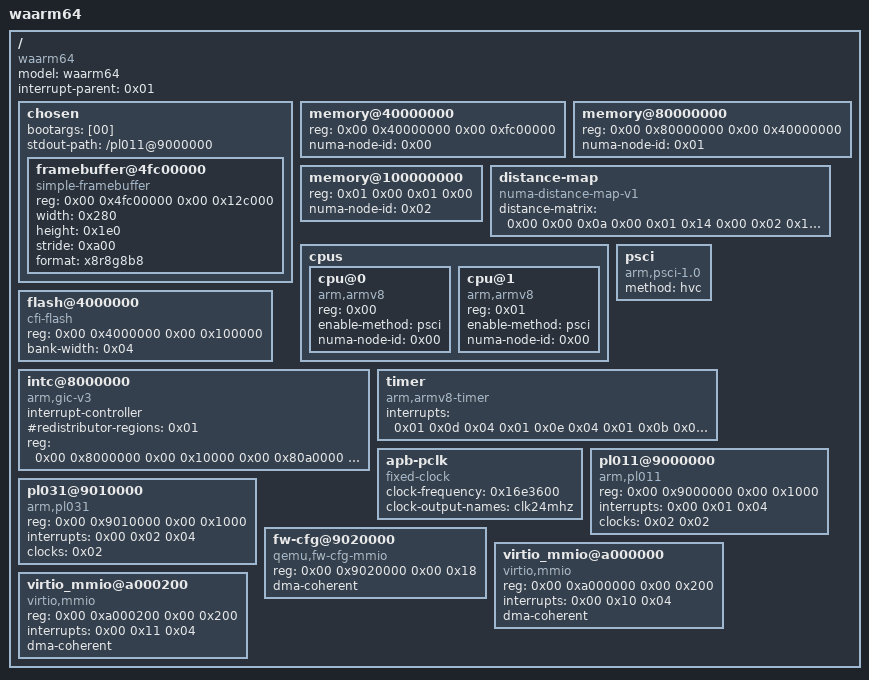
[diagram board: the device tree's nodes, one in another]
/dts-v1/;

/ {
	#address-cells = <0x02>;
	#size-cells = <0x02>;
	compatible = "waarm64", "linux,dummy-virt";
	model = "waarm64";
	interrupt-parent = <0x01>;

	chosen {
		bootargs = [00];
		stdout-path = "/pl011@9000000";
		#address-cells = <0x02>;
		#size-cells = <0x02>;
		ranges;

		framebuffer@4fc00000 {
			compatible = "simple-framebuffer";
			reg = <0x00 0x4fc00000 0x00 0x12c000>;
			width = <0x280>;
			height = <0x1e0>;
			stride = <0xa00>;
			format = "x8r8g8b8";
		};
	};

	memory@40000000 {
		device_type = "memory";
		reg = <0x00 0x40000000 0x00 0xfc00000>;
		numa-node-id = <0x00>;
	};

	memory@80000000 {
		device_type = "memory";
		reg = <0x00 0x80000000 0x00 0x40000000>;
		numa-node-id = <0x01>;
	};

	memory@100000000 {
		device_type = "memory";
		reg = <0x01 0x00 0x01 0x00>;
		numa-node-id = <0x02>;
	};

	distance-map {
		compatible = "numa-distance-map-v1";
		distance-matrix = <0x00 0x00 0x0a 0x00 0x01 0x14 0x00 0x02 0x14 0x01 0x00 0x14 0x01 0x01 0x0a 0x01 0x02 0x14 0x02 0x00 0x14 0x02 0x01 0x14 0x02 0x02 0x0a>;
	};

	cpus {
		#address-cells = <0x01>;
		#size-cells = <0x00>;

		cpu@0 {
			device_type = "cpu";
			compatible = "arm,armv8";
			reg = <0x00>;
			enable-method = "psci";
			numa-node-id = <0x00>;
		};

		cpu@1 {
			device_type = "cpu";
			compatible = "arm,armv8";
			reg = <0x01>;
			enable-method = "psci";
			numa-node-id = <0x00>;
		};
	};

	psci {
		compatible = "arm,psci-1.0", "arm,psci-0.2";
		method = "hvc";
	};

	flash@4000000 {
		compatible = "cfi-flash";
		reg = <0x00 0x4000000 0x00 0x100000>;
		bank-width = <0x04>;
	};

	intc@8000000 {
		compatible = "arm,gic-v3";
		#interrupt-cells = <0x03>;
		interrupt-controller;
		#redistributor-regions = <0x01>;
		reg = <0x00 0x8000000 0x00 0x10000 0x00 0x80a0000 0x00 0x40000>;
		phandle = <0x01>;
	};

	timer {
		compatible = "arm,armv8-timer";
		interrupts = <0x01 0x0d 0x04 0x01 0x0e 0x04 0x01 0x0b 0x04 0x01 0x0a 0x04>;
	};

	apb-pclk {
		compatible = "fixed-clock";
		#clock-cells = <0x00>;
		clock-frequency = <0x16e3600>;
		clock-output-names = "clk24mhz";
		phandle = <0x02>;
	};

	pl011@9000000 {
		compatible = "arm,pl011", "arm,primecell";
		reg = <0x00 0x9000000 0x00 0x1000>;
		interrupts = <0x00 0x01 0x04>;
		clocks = <0x02 0x02>;
		clock-names = "uartclk", "apb_pclk";
	};

	pl031@9010000 {
		compatible = "arm,pl031", "arm,primecell";
		reg = <0x00 0x9010000 0x00 0x1000>;
		interrupts = <0x00 0x02 0x04>;
		clocks = <0x02>;
		clock-names = "apb_pclk";
	};

	fw-cfg@9020000 {
		compatible = "qemu,fw-cfg-mmio";
		reg = <0x00 0x9020000 0x00 0x18>;
		dma-coherent;
	};

	virtio_mmio@a000000 {
		compatible = "virtio,mmio";
		reg = <0x00 0xa000000 0x00 0x200>;
		interrupts = <0x00 0x10 0x04>;
		dma-coherent;
	};

	virtio_mmio@a000200 {
		compatible = "virtio,mmio";
		reg = <0x00 0xa000200 0x00 0x200>;
		interrupts = <0x00 0x11 0x04>;
		dma-coherent;
	};
};
